# APM32F446 register map
File version: 1.0
CPU: CM4 r0p1, little endian, MPU, FPU, 4 interrupt priority bits
Registers are 32-bit, read-write, reset 0x0 unless marked. A register's access mark holds for its fields unless they carry their own. Offsets are from the block's base; [hi:lo] are bit positions; {n}, {i} and the like mark numbered series; 'fields as' and 'values as' point back to an identical list.

## CFGTMR0 — Configurable Timer
Base 0x40038000
Same registers: CFGTMR3 0x40026000, CFGTMR1 0x40039000, CFGTMR2 0x4003A000, CFGTMR4 0x4006E000, CFGTMR5 0x4006F000
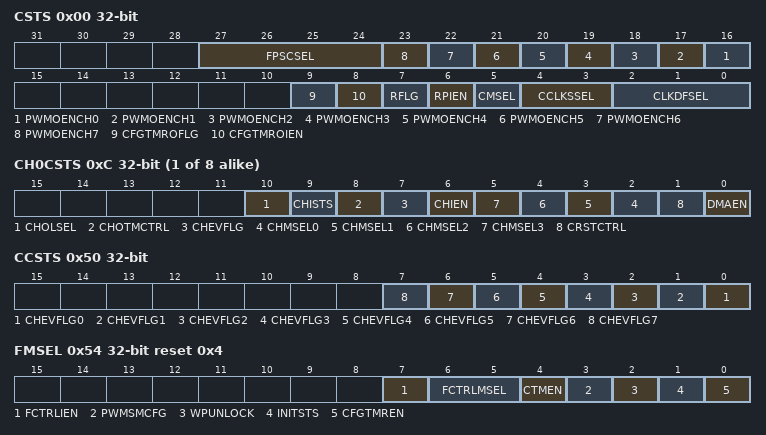
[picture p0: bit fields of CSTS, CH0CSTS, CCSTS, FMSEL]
0x00 CSTS — Control and Status Register
  [27:24] FPSCSEL — Filter Prescale Select
    {v}=Divide by {v+1} (v=0..15)
  [n+16] PWMOENCH{n} (n=0..7) — PWM Channel 0-7 Output Enable
    0=Channel output port is disabled; 1=Channel output port is enabled
  [9] CFGTMROFLG — CFGTMR Overflow Flag
    0=CFGTMR counter has not overflowed; 1=CFGTMR counter has overflowed
  [8] CFGTMROIEN — CFGTMR Overflow Interrupt Enable
    0=Disable TOF interrupts. Use software polling.; 1=Enable TOF interrupts. An interrupt is generated when TOF equals one.
  [7] RFLG — Reload Flag
    0=A selected reload point did not happen; 1=A selected reload point happened
  [6] RPIEN — Reload Point Interrupt Enable
    0=Reload point interrupt is disabled; 1=Reload point interrupt is enabled
  [5] CMSEL — CFGTMR Counter Mode Select
    0=CFGTMR counter operates in Up Counting mode; 1=CFGTMR counter operates in Up-Down Counting mode
  [4:3] CCLKSSEL — Counter Clock Source Select
    0=No clock selected. This in effect disables the CFGTMR counter.; 1=CFGTMR input clock; 2=Fixed frequency clock; 3=External clock
  [2:0] CLKDFSEL — Clock Division Factor Select
    0=Divide by 1; 1=Divide by 2; 2=Divide by 4; 3=Divide by 8; 4=Divide by 16; 5=Divide by 32; 6=Divide by 64; 7=Divide by 128
0x04 CNT — Counter Register
  [15:0] CNT — Counter Value
0x08 MOD — Modulo Register
  [15:0] MOD — Modulo Value
{0xC+8i} CH{i}CSTS (i=0..7) — Channel (n) Control And Status Register
  [10] CHOLSEL ro — Channel (n) Output Value Select
    0=The channel (n) output is zero; 1=The channel (n) output is one
  [9] CHISTS ro — Channel (n) Input State
    0=The channel (n) input is zero; 1=The channel (n) input is one
  [8] CHOTMCTRL — Channel (n) Output Trigger Mode Control
    0=Channel outputs will generate the normal PWM outputs without generating a pulse; 1=If a match in the channel occurs, a trigger generation on channel output will happen. The trigger pulse width has one CFGTMR clock cycle.
  [7] CHEVFLG — Channel (n) Event Flag
    0=No channel (n) event has occurred; 1=A channel (n) event has occurred
  [6] CHIEN — Channel (n) Interrupt Enable
    0=Disable channel (n) interrupt. Use software polling.; 1=Enable channel (n) interrupt
  [n+2] CHMSEL{n} (n=0..3) — Channel (n) Mode Select {n}
  [1] CRSTCTRL — CFGTMR Counter Reset Control
    0=CFGTMR counter is not reset when the selected channel (n) input event is detected; 1=CFGTMR counter is reset when the selected channel (n) input event is detected
  [0] DMAEN — DMA Enable
    0=Disable DMA transfers; 1=Enable DMA transfers
{0x10+8i} CH{i}V (i=0..7) — Channel (n) Value Register
  [15:0] CHV — Channel Value
0x4C INITV — Initial Value Register
  [15:0] INITV — Initial Value
0x50 CCSTS — Capture and Compare Status Register
  [n] CHEVFLG{n} (n=0..7) ro — Channel 0-7 Flag
    0=No channel event has occurred; 1=A channel event has occurred
0x54 FMSEL reset 0x4 — Features Mode Select Register
  [7] FCTRLIEN — Fault Control Interrupt Enable
    0=Fault control interrupt is disabled; 1=Fault control interrupt is enabled
  [6:5] FCTRLMSEL — Fault Control Mode Select
    0=Fault control is disabled for all channels; 1=Fault control is enabled for even channels only (channels 0, 2, 4, and 6), and the selected mode is the manual fault clearing; 2=Fault control is enabled for all channels, and the selected mode is the manual fault clearing; 3=Fault control is enabled for all channels, and the selected mode is the automatic fault clearing
  [4] CTMEN — Capture Test Mode Enable
    0=Capture test mode is disabled; 1=Capture test mode is enabled
  [3] PWMSMCFG — PWM Synchronization Mode Configure
    0=No restrictions. Software and hardware triggers can be used by MOD, CHnV, OMASK, and CFGTMR counter synchronization.; 1=Software trigger can only be used by MOD and CHnV synchronization, and hardware triggers can only be used by OMASK and CFGTMR counter synchronization
  [2] WPUNLOCK — Write Protection unlock
    0=Write protection is enabled; 1=Write protection is disabled
  [1] INITSTS wo — Channels Output Initialization Status
  [0] CFGTMREN — CFGTMR Module Enable
    0=TPM compatibility. Free running counter and synchronization compatible with TPM.; 1=Free running counter and synchronization are different from TPM behavior
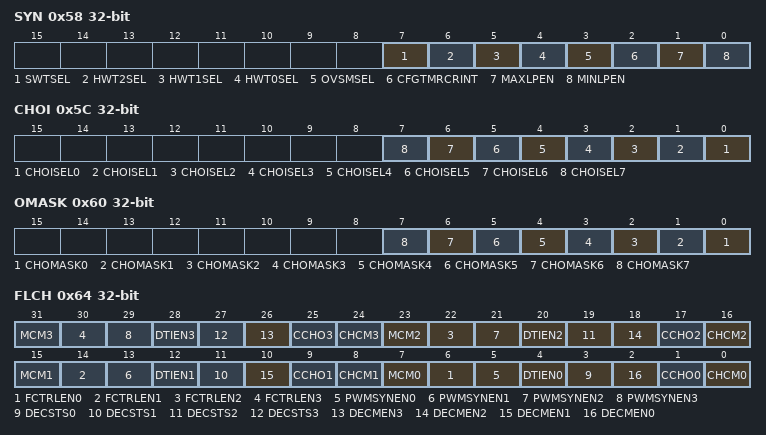
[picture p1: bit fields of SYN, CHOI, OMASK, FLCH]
0x58 SYN — Synchronization Register
  [7] SWTSEL — PWM Synchronization Software Trigger Select
    0=Software trigger is not selected; 1=Software trigger is selected
  [6] HWT2SEL — PWM Synchronization Hardware Trigger 2 Select
    0=Trigger is disabled; 1=Trigger is enabled
  [5] HWT1SEL — PWM Synchronization Hardware Trigger 1 Select
    0=Trigger is disabled; 1=Trigger is enabled
  [4] HWT0SEL — PWM Synchronization Hardware Trigger 0 Select
    0=Trigger is disabled; 1=Trigger is enabled
  [3] OVSMSEL — Output Value Synchronization Mode Select
    0=OMASK register is updated with the value of its buffer in all rising edges of the CFGTMR input clock; 1=OMASK register is updated with the value of its buffer only by the PWM synchronization
  [2] CFGTMRCRINT — Reinitialization CFGTMR Counter Value Synchronization
    0=CFGTMR counter continues to count normally; 1=CFGTMR counter is updated with its initial value when the selected trigger is detected
  [1] MAXLPEN — Maximum Loading Point Enable
    0=The maximum loading point is disabled; 1=The maximum loading point is enabled
  [0] MINLPEN — Minimum Loading Point Enable
    0=The minimum loading point is disabled; 1=The minimum loading point is enabled
0x5C CHOI — Channel Output Initialization Register
  [n] CHOISEL{n} (n=0..7) — Channel 0-7 Output Initialization Value
    0=The initialization value is 0; 1=The initialization value is 1
0x60 OMASK — Output Mask Register
  [n] CHOMASK{n} (n=0..7) — Channel 0-7 Output Mask
    0=Channel output is not masked. It continues to operate normally.; 1=Channel output is masked. It is forced to its inactive state.
0x64 FLCH — Function For Linked Channels Register
  [8n+7] MCM{n} (n=0..3) — Modified Combine Mode For n={2n}
  [8n+6] FCTRLEN{n} (n=0..3) — Fault Control Enable For n={2n}
    0=The fault control in this pair of channels is disabled; 1=The fault control in this pair of channels is enabled
  [8n+5] PWMSYNEN{n} (n=0..3) — PWM Synchronization Enable For n={2n}
    0=The PWM synchronization in this pair of channels is disabled; 1=The PWM synchronization in this pair of channels is enabled
  [8n+4] DTIEN{n} (n=0..3) — Deadtime Insertion Enable For n={2n}
    0=The deadtime insertion in this pair of channels is disabled; 1=The deadtime insertion in this pair of channels is enabled
  [8n+3] DECSTS{n} (n=0..3) — Dual Edge Capture Status For n={2n}
    0=The dual edge captures are inactive; 1=The dual edge captures are active
  [26] DECMEN3 — Dual Edge Capture Mode Enable For n=6
  [25] CCHO3 — Complement Channel (n) Output for n=6
    0=The channel (n+1) output is the same as the channel (n) output; 1=The channel (n+1) output is the complement of the channel (n) output
  [8n] CHCM{n} (n=0..3) — Channels Combine Mode For n={2n}
  [18] DECMEN2 — Dual Edge Capture Mode Enable For n=4
  [17] CCHO2 — Complement Channel (n) Output for n=4
    values as CCHO3
  [10] DECMEN1 — Dual Edge Capture Status For n=2
  [9] CCHO1 — Dual Edge Capture Mode Enable For n=2
    values as CCHO3
  [2] DECMEN0 — Dual Edge Capture Mode Enable For n=0
  [1] CCHO0 — Complement Channel (n) Output for n=0
    values as CCHO3
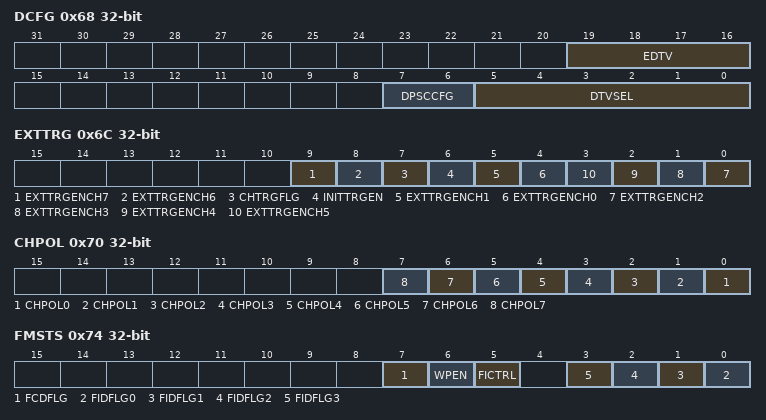
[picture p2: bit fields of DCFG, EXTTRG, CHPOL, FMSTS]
0x68 DCFG — Deadtime Configure Register
  [19:16] EDTV — Extended Deadtime Value
  [7:6] DPSCCFG — Deadtime Prescaler Factor Configure
    0b0x=Divide the CFGTMR input clock by 1; 2=Divide the CFGTMR input clock by 4; 3=Divide the CFGTMR input clock by 16
  [5:0] DTVSEL — Deadtime Value Select
0x6C EXTTRG — External Trigger Register
  [9] EXTTRGENCH7 — Channel 7 External Trigger Generation Enable
    0=The generation of this external trigger is disabled; 1=The generation of this external trigger is enabled
  [8] EXTTRGENCH6 — Channel 6 External Trigger Generation Enable
    values as EXTTRGENCH7
  [7] CHTRGFLG — Channel Trigger Flag
    0=No channel trigger was generated; 1=A channel trigger was generated
  [6] INITTRGEN — Initialization Trigger Generate Enable
    0=The generation of initialization trigger is disabled; 1=The generation of initialization trigger is enabled
  [5] EXTTRGENCH1 — Channel 1 External Trigger Generation Enable
    values as EXTTRGENCH7
  [4] EXTTRGENCH0 — Channel 0 External Trigger Generation Enable
    values as EXTTRGENCH7
  [n-2] EXTTRGENCH{n} (n=2..5) — Channel {n} External Trigger Generation Enable
    values as EXTTRGENCH7
0x70 CHPOL — Channel Output Polarity Register
  [n] CHPOL{n} (n=0..7) — Channel 0-7 Output Polarity
    0=The channel polarity is active high; 1=The channel polarity is active low
0x74 FMSTS — Fault module status register
  [7] FCDFLG ro — Fault Condition Detection Flag
    0=No fault condition was detected; 1=A fault condition was detected
  [6] WPEN — Write Protection Enable
    0=Write protection is disabled. Write protected bits can be written.; 1=Write protection is enabled. Write protected bits cannot be written.
  [5] FICTRL — Fault Inputs Control
    0=The logic OR of the enabled fault inputs is 0; 1=The logic OR of the enabled fault inputs is 1
  [n] FIDFLG{n} (n=0..3) — Fault Inputs Detection Flag {n}
    0=No fault condition was detected at the fault input; 1=A fault condition was detected at the fault input
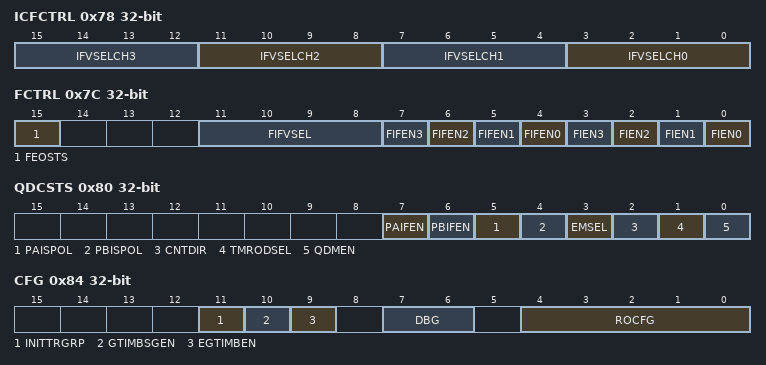
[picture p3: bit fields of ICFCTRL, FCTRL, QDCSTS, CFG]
0x78 ICFCTRL — Input Capture Filter Control Register
  [4n+3:4n] IFVSELCH{n} (n=0..3) — Channel {n} Input Filter Value Select
0x7C FCTRL — Fault Control Register
  [15] FEOSTS — Fault Event Output Status
    0=CFGTMR outputs will be placed into safe values when fault events in ongoing (defined by POL bits); 1=CFGTMR outputs will be tri-stated when fault event is ongoing
  [11:8] FIFVSEL — Fault Input Filter Value Select
  [n+4] FIFEN{n} (n=0..3) — Fault Input Filter {n} Enable
    0=Fault input filter is disabled; 1=Fault input filter is enabled
  [n] FIEN{n} (n=0..3) — Fault Input {n} Enable
    0=Fault input is disabled; 1=Fault input is enabled
0x80 QDCSTS — Quadrature Decoder Control And Status Register
  [7] PAIFEN — Phase A Input Filter Value Enable
    0=Phase A input filter is disabled; 1=Phase A input filter is enabled
  [6] PBIFEN — Phase B Input Filter Value Enable
    0=Phase B input filter is disabled; 1=Phase B input filter is enabled
  [5] PAISPOL — Phase A Input Signal Polarity Select
    0=Normal polarity. Phase A input signal is not inverted before identifying the rising and falling edges of this signal.; 1=Inverted polarity. Phase A input signal is inverted before identifying the rising and falling edges of this signal.
  [4] PBISPOL — Phase B Input Signal Polarity Select
    0=Normal polarity. Phase B input signal is not inverted before identifying the rising and falling edges of this signal.; 1=Inverted polarity. Phase B input signal is inverted before identifying the rising and falling edges of this signal.
  [3] EMSEL — Encoding Mode Select
    0=Phase A and phase B encoding mode; 1=Count and direction encoding mode
  [2] CNTDIR ro — CFGTMR Counter Direction
    0=Counting direction is decreasing (CFGTMR counter decrement); 1=Counting direction is increasing (CFGTMR counter increment)
  [1] TMRODSEL ro — Timer Overflow Direction Select
    0=TOF bit was set on the bottom of counting. There was an CFGTMR counter decrement and CFGTMR counter changes from its minimum value (INITV register) to its maximum value (MOD register).; 1=TOF bit was set on the top of counting. There was an CFGTMR counter increment and CFGTMR counter changes from its maximum value (MOD register) to its minimum value (INITV register).
  [0] QDMEN — Quadrature Decoder Mode Enable
    0=Quadrature Decoder mode is disabled; 1=Quadrature Decoder mode is enabled
0x84 CFG — Configure Register
  [11] INITTRGRP — Initialization Trigger on Reload Point
    0=Initialization trigger is generated on counter wrap events; 1=Initialization trigger is generated when a reload point is reached
  [10] GTIMBSGEN — Global Time Base Signal Generation Enable
  [9] EGTIMBEN — External Global Time Base Enable
  [7:6] DBG — Debug Mode
  [4:0] ROCFG — Reload Opportunities Configure
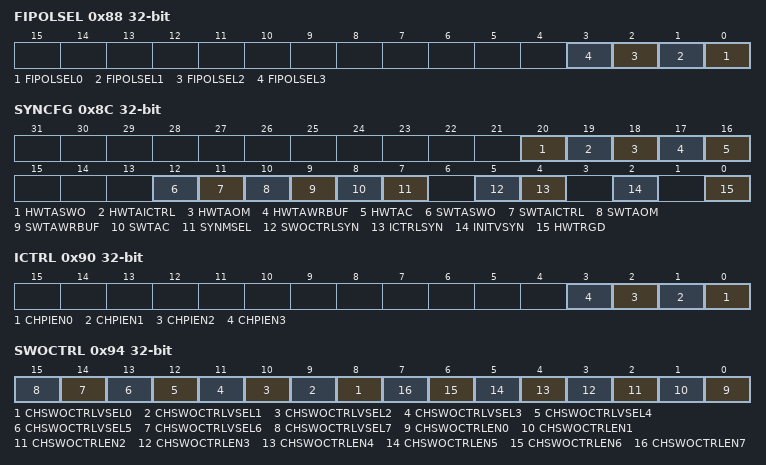
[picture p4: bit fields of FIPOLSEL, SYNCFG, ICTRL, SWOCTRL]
0x88 FIPOLSEL — Fault Input Polarity Select Register
  [all] fields
    0=The fault input polarity is active high. A 1 at the fault input indicates a fault.; 1=The fault input polarity is active low. A 0 at the fault input indicates a fault.
  [n] FIPOLSEL{n} (n=0..3) — Fault Input {n} Polarity Select
0x8C SYNCFG — Synchronization Configure Register
  [20] HWTASWO — Hardware Trigger Activates CFGTMR_SWOCTRL Register Synchronization
    0=A hardware trigger does not activate the SWOCTRL register synchronization; 1=A hardware trigger activates the SWOCTRL register synchronization
  [19] HWTAICTRL — Hardware Trigger Activates CFGTMR_ICTRL Register Synchronization
    0=A hardware trigger does not activate the ICTRL register synchronization; 1=A hardware trigger activates the ICTRL register synchronization
  [18] HWTAOM — Hardware Trigger Activates CFGTMR_OMASK Register Synchronization
    0=A hardware trigger does not activate the OMASK register synchronization; 1=A hardware trigger activates the OMASK register synchronization
  [17] HWTAWRBUF — Hardware Trigger Activates CFGTMR_MOD,CFGTMR_HC,CFGTMR_INITV and CFGTMR_CHnV (n=0...7) Register Synchronization
    0=A hardware trigger does not activate MOD, HC, INITV, and COMPVAL registers synchronization; 1=A hardware trigger activates MOD, HC, INITV, and COMPVAL registers synchronization
  [16] HWTAC — Hardware Trigger Activates CFGTMR Counter Register Synchronization
    0=A hardware trigger does not activate the CFGTMR counter synchronization; 1=A hardware trigger activates the CFGTMR counter synchronization
  [12] SWTASWO — Software Trigger Activates CFGTMR_SWOCTRL Register Synchronization
    0=The software trigger does not activate the SWOCTRL register synchronization; 1=The software trigger activates the SWOCTRL register synchronization
  [11] SWTAICTRL — Software Trigger Activates CFGTMR_ICTRL Register Synchronization
    0=The software trigger does not activate the ICTRL register synchronization; 1=The software trigger activates the ICTRL register synchronization
  [10] SWTAOM — Software Trigger Activates CFGTMR_OMASK Register Synchronization
    0=The software trigger does not activate the OMASK register synchronization; 1=The software trigger activates the OMASK register synchronization
  [9] SWTAWRBUF — Software Trigger Activates CFGTMR_MOD,CFGTMR_HC,CFGTMR_INITV and CFGTMR_CHnV (n=0...7) Register Synchronization
    0=The software trigger does not activate MOD, HC, INITV, and COMPVAL registers synchronization; 1=The software trigger activates MOD, HC, INITV, and COMPVAL registers synchronization
  [8] SWTAC — Software Trigger Activates CFGTMR Counter Register Synchronization
    0=The software trigger does not activate the CFGTMR counter synchronization; 1=The software trigger activates the CFGTMR counter synchronization
  [7] SYNMSEL — Synchronization Mode Select
    0=Legacy PWM synchronization is selected; 1=Enhanced PWM synchronization is selected
  [5] SWOCTRLSYN — CFGTMR_SWOCTRL Register Synchronization
    0=SWOCTRL register is updated with its buffer value at all rising edges of CFGTMR input clock; 1=SWOCTRL register is updated with its buffer value by the PWM synchronization
  [4] ICTRLSYN — CFGTMR_ICTRL Register Synchronization
    0=ICTRL register is updated with its buffer value at all rising edges of CFGTMR input clock; 1=ICTRL register is updated with its buffer value by the PWM synchronization
  [2] INITVSYN — CFGTMR_INITV Register Synchronization
    0=INITV register is updated with its buffer value at all rising edges of CFGTMR input clock; 1=INITV register is updated with its buffer value by the PWM synchronization
  [0] HWTRGD — Hardware Trigger Detect
    0=CFGTMR clears the PRDTRENj bit when the hardware trigger j is detected, where j = 0,1,2; 1=CFGTMR does not clear the PRDTRENj bit when the hardware trigger j is detected, where j = 0,1,2
0x90 ICTRL — Inverting Control Register
  [all] fields
    0=Inverting is disabled; 1=Inverting is enabled
  [n] CHPIEN{n} (n=0..3) — Channels Pair {n} Inverting Enable
0x94 SWOCTRL — Software Output Control Register
  [n+8] CHSWOCTRLVSEL{n} (n=0..7) — Channel 0-7 Software Output Control Value
    0=The software output control forces 0 to the channel output; 1=The software output control forces 1 to the channel output
  [n] CHSWOCTRLEN{n} (n=0..7) — Channel 0-7 Software Output Control Enable
    0=The channel output is not affected by software output control; 1=The channel output is affected by software output control
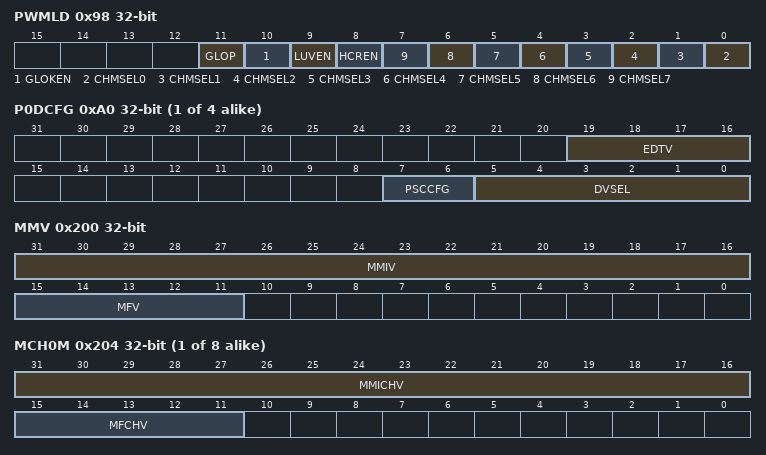
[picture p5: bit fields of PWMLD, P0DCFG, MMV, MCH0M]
0x98 PWMLD — PWM Load Register
  [11] GLOP wo — Global Load OK Present
    0=No action; 1=LDOK bit is set
  [10] GLOKEN — Global Load OK Enable
    0=Global Load Ok disabled; 1=Global Load OK enabled. A pulse event on the module global load input sets the LDOK bit.
  [9] LUVEN — Load Updated Values Enable
    0=Loading updated values is disabled; 1=Loading updated values is enabled
  [8] HCREN — Half Cycle Reload Enable
    0=Half cycle reload is disabled and it is not considered as a reload opportunity; 1=Half cycle reload is enabled and it is considered as a reload opportunity
  [n] CHMSEL{n} (n=0..7) — Channel 0-7 Match Select
    0=Channel match is not included as a reload opportunity; 1=Channel match is included as a reload opportunity
0x9C HC — Half Cycle Register
  [15:0] HCV — Half Cycle Value
{0xA0+8i} P{i}DCFG (i=0..3) — Pair x Deadtime Configure Register
  [19:16] EDTV — Extended Deadtime Value
  [7:6] PSCCFG — Deadtime Prescaler Factor Configure
    values as DCFG.DPSCCFG
  [5:0] DVSEL — Deadtime Value Select
0x200 MMV — Mirror of Modulo Value Register
  [31:16] MMIV — Mirror of Modulo Integer Value
  [15:11] MFV — Modulo Fractional Value
{0x204+4i} MCH{i}M (i=0..7) — Mirror of Channel (n) Match Value Register
  [31:16] MMICHV — Mirror of the Channel (n) Match Integer Value
  [15:11] MFCHV — Channel (n) Match Fractional Value
